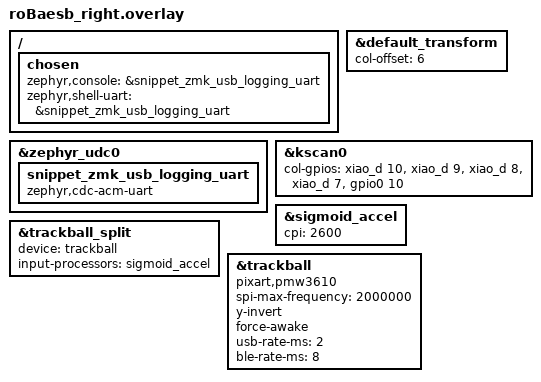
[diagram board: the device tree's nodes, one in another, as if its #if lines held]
#include "../roBa/roBa.dtsi"
#include "../roBa/roBa_R_trackball.dtsi"
#ifdef ZMK_ESB_ADDR_B
#include "roBaesb_addr_b.dtsi"
#else
#include "roBaesb_addr.dtsi"
#endif
#include <input/processors/xyz.dtsi>
#include <behaviors/input_processor_sigmoid_accel.dtsi>

/ {
    chosen {
        zephyr,console = &snippet_zmk_usb_logging_uart;
        zephyr,shell-uart = &snippet_zmk_usb_logging_uart;
    };
};

&zephyr_udc0 {
    snippet_zmk_usb_logging_uart: snippet_zmk_usb_logging_uart {
        compatible = "zephyr,cdc-acm-uart";
    };
};

&default_transform {
    col-offset = <6>;
};

&kscan0 {
    col-gpios
        = <&xiao_d 10 GPIO_ACTIVE_HIGH>
        , <&xiao_d 9 GPIO_ACTIVE_HIGH>
        , <&xiao_d 8 GPIO_ACTIVE_HIGH>
        , <&xiao_d 7 GPIO_ACTIVE_HIGH>
        , <&gpio0 10 GPIO_ACTIVE_HIGH>
        ;
};

&sigmoid_accel {
    cpi = <2600>;
};

&trackball_split {
    status = "okay";
    device = <&trackball>;
    input-processors = <&sigmoid_accel>;
};

&trackball {
    compatible = "pixart,pmw3610";
    spi-max-frequency = <2000000>;
    y-invert;
    force-awake;
    /delete-property/ invert-y;
    /* Output-driven rate switching (CONFIG_PMW3610_OUTPUT_RATE_NOTIFY).
     * The central broadcasts USB/BLE over ESB; the driver picks the rate.
     * 2 = ~500 Hz (USB), 8 = 125 Hz (BLE). usb-rate-ms also sets the boot rate. */
    usb-rate-ms = <2>;
    ble-rate-ms = <8>;
};
